AUTOSAR XML (schema 4-2-2)
package /STELLANTIS/EPT/ASWCs
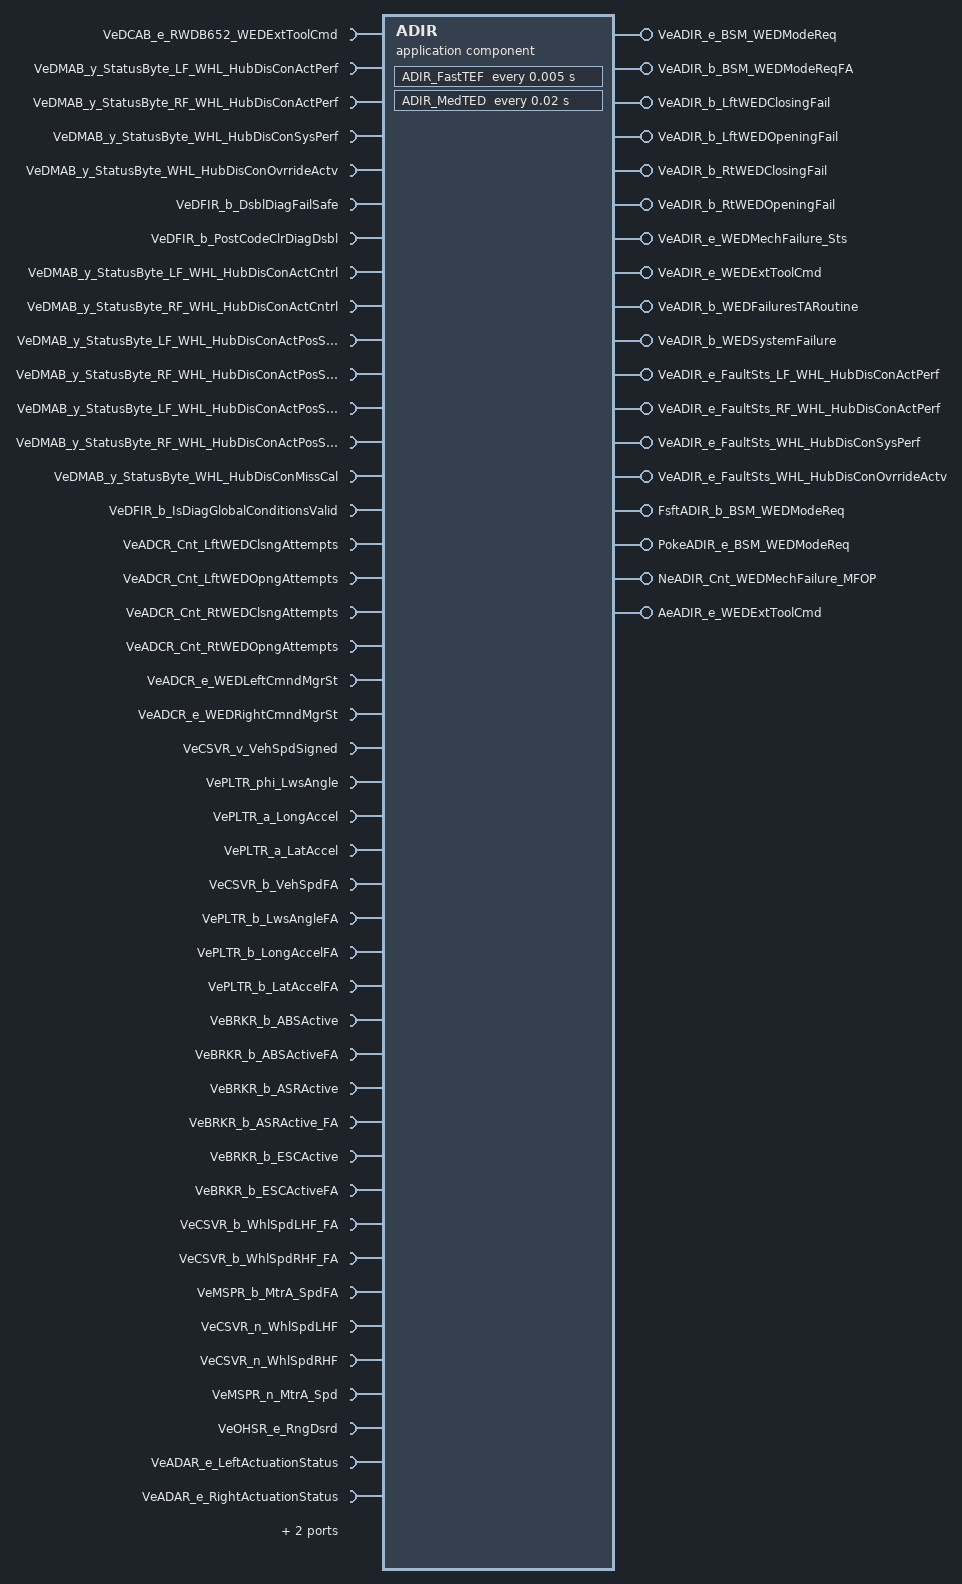
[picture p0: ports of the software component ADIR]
  application sw component type ADIR
    44 x require port:
      VeDCAB_e_RWDB652_WEDExtToolCmd: variation-point={short-label=vpVeDCAB_e_RWDB652_WEDExtToolCmd, sw-syscond=1}, nonqueued-receiver-com-spec{data-element=Value, init-value=CeADIR_e_ECUNormalControl}, required-interface=VeDCAB_e_RWDB652_WEDExtToolCmd
      VeDMAB_y_StatusByte_LF_WHL_HubDisConActPerf: variation-point={short-label=vpVeDMAB_y_StatusByte_LF_WHL_HubDisConActPerf, sw-syscond=1}, nonqueued-receiver-com-spec{data-element=Value, init-value=0}, required-interface=VeDMAB_y_StatusByte_LF_WHL_HubDisConActPerf
      VeDMAB_y_StatusByte_RF_WHL_HubDisConActPerf: variation-point={short-label=vpVeDMAB_y_StatusByte_RF_WHL_HubDisConActPerf, sw-syscond=1}, nonqueued-receiver-com-spec{data-element=Value, init-value=0}, required-interface=VeDMAB_y_StatusByte_RF_WHL_HubDisConActPerf
      VeDMAB_y_StatusByte_WHL_HubDisConSysPerf: variation-point={short-label=vpVeDMAB_y_StatusByte_WHL_HubDisConSysPerf, sw-syscond=1}, nonqueued-receiver-com-spec{data-element=Value, init-value=0}, required-interface=VeDMAB_y_StatusByte_WHL_HubDisConSysPerf
      VeDMAB_y_StatusByte_WHL_HubDisConOvrrideActv: variation-point={short-label=vpVeDMAB_y_StatusByte_WHL_HubDisConOvrrideActv, sw-syscond=1}, nonqueued-receiver-com-spec{data-element=Value, init-value=0}, required-interface=VeDMAB_y_StatusByte_WHL_HubDisConOvrrideActv
      VeDFIR_b_DsblDiagFailSafe: variation-point={short-label=vpVeDFIR_b_DsblDiagFailSafe, sw-syscond=1}, nonqueued-receiver-com-spec{data-element=Value, init-value=0}, required-interface=VeDFIR_b_DsblDiagFailSafe
      VeDFIR_b_PostCodeClrDiagDsbl: variation-point={short-label=vpVeDFIR_b_PostCodeClrDiagDsbl, sw-syscond=1}, nonqueued-receiver-com-spec{data-element=Value, init-value=0}, required-interface=VeDFIR_b_PostCodeClrDiagDsbl
      VeDMAB_y_StatusByte_LF_WHL_HubDisConActCntrl: variation-point={short-label=vpVeDMAB_y_StatusByte_LF_WHL_HubDisConActCntrl, sw-syscond=1}, nonqueued-receiver-com-spec{data-element=Value, init-value=0}, required-interface=VeDMAB_y_StatusByte_LF_WHL_HubDisConActCntrl
      VeDMAB_y_StatusByte_RF_WHL_HubDisConActCntrl: variation-point={short-label=vpVeDMAB_y_StatusByte_RF_WHL_HubDisConActCntrl, sw-syscond=1}, nonqueued-receiver-com-spec{data-element=Value, init-value=0}, required-interface=VeDMAB_y_StatusByte_RF_WHL_HubDisConActCntrl
      VeDMAB_y_StatusByte_LF_WHL_HubDisConActPosSnsr: variation-point={short-label=vpVeDMAB_y_StatusByte_LF_WHL_HubDisConActPosSnsr, sw-syscond=1}, nonqueued-receiver-com-spec{data-element=Value, init-value=0}, required-interface=VeDMAB_y_StatusByte_LF_WHL_HubDisConActPosSnsr
      VeDMAB_y_StatusByte_RF_WHL_HubDisConActPosSnsr: variation-point={short-label=vpVeDMAB_y_StatusByte_RF_WHL_HubDisConActPosSnsr, sw-syscond=1}, nonqueued-receiver-com-spec{data-element=Value, init-value=0}, required-interface=VeDMAB_y_StatusByte_RF_WHL_HubDisConActPosSnsr
      VeDMAB_y_StatusByte_LF_WHL_HubDisConActPosSnsrCktPerf: variation-point={short-label=vpVeDMAB_y_StatusByte_LF_WHL_HubDisConActPosSnsrCktPerf, sw-syscond=1}, nonqueued-receiver-com-spec{data-element=Value, init-value=0}, required-interface=VeDMAB_y_StatusByte_LF_WHL_HubDisConActPosSnsrCktPerf
      VeDMAB_y_StatusByte_RF_WHL_HubDisConActPosSnsrCktPerf: variation-point={short-label=vpVeDMAB_y_StatusByte_RF_WHL_HubDisConActPosSnsrCktPerf, sw-syscond=1}, nonqueued-receiver-com-spec{data-element=Value, init-value=0}, required-interface=VeDMAB_y_StatusByte_RF_WHL_HubDisConActPosSnsrCktPerf
      VeDMAB_y_StatusByte_WHL_HubDisConMissCal: variation-point={short-label=vpVeDMAB_y_StatusByte_WHL_HubDisConMissCal, sw-syscond=1}, nonqueued-receiver-com-spec{data-element=Value, init-value=0}, required-interface=VeDMAB_y_StatusByte_WHL_HubDisConMissCal
      VeDFIR_b_IsDiagGlobalConditionsValid: variation-point={short-label=vpVeDFIR_b_IsDiagGlobalConditionsValid, sw-syscond=1}, nonqueued-receiver-com-spec{data-element=Value, init-value=0}, required-interface=VeDFIR_b_IsDiagGlobalConditionsValid
      VeADCR_Cnt_LftWEDClsngAttempts: variation-point={short-label=vpVeADCR_Cnt_LftWEDClsngAttempts, sw-syscond=1}, nonqueued-receiver-com-spec{data-element=Value, init-value=0}, required-interface=VeADCR_Cnt_LftWEDClsngAttempts
      VeADCR_Cnt_LftWEDOpngAttempts: variation-point={short-label=vpVeADCR_Cnt_LftWEDOpngAttempts, sw-syscond=1}, nonqueued-receiver-com-spec{data-element=Value, init-value=0}, required-interface=VeADCR_Cnt_LftWEDOpngAttempts
      VeADCR_Cnt_RtWEDClsngAttempts: variation-point={short-label=vpVeADCR_Cnt_RtWEDClsngAttempts, sw-syscond=1}, nonqueued-receiver-com-spec{data-element=Value, init-value=0}, required-interface=VeADCR_Cnt_RtWEDClsngAttempts
      VeADCR_Cnt_RtWEDOpngAttempts: variation-point={short-label=vpVeADCR_Cnt_RtWEDOpngAttempts, sw-syscond=1}, nonqueued-receiver-com-spec{data-element=Value, init-value=0}, required-interface=VeADCR_Cnt_RtWEDOpngAttempts
      VeADCR_e_WEDLeftCmndMgrSt: variation-point={short-label=vpVeADCR_e_WEDLeftCmndMgrSt, sw-syscond=1}, nonqueued-receiver-com-spec{data-element=Value, init-value=CeADCR_e_WEDCmndInit}, required-interface=VeADCR_e_WEDLeftCmndMgrSt
      VeADCR_e_WEDRightCmndMgrSt: variation-point={short-label=vpVeADCR_e_WEDRightCmndMgrSt, sw-syscond=1}, nonqueued-receiver-com-spec{data-element=Value, init-value=CeADCR_e_WEDCmndInit}, required-interface=VeADCR_e_WEDRightCmndMgrSt
      VeCSVR_v_VehSpdSigned: variation-point={short-label=vpVeCSVR_v_VehSpdSigned, sw-syscond=1}, nonqueued-receiver-com-spec{data-element=Value, init-value=0}, required-interface=VeCSVR_v_VehSpdSigned
      VePLTR_phi_LwsAngle: variation-point={short-label=vpVePLTR_phi_LwsAngle, sw-syscond=1}, nonqueued-receiver-com-spec{data-element=Value, init-value=0}, required-interface=VePLTR_phi_LwsAngle
      VePLTR_a_LongAccel: variation-point={short-label=vpVePLTR_a_LongAccel, sw-syscond=1}, nonqueued-receiver-com-spec{data-element=Value, init-value=0}, required-interface=VePLTR_a_LongAccel
      VePLTR_a_LatAccel: variation-point={short-label=vpVePLTR_a_LatAccel, sw-syscond=1}, nonqueued-receiver-com-spec{data-element=Value, init-value=0}, required-interface=VePLTR_a_LatAccel
      VeCSVR_b_VehSpdFA: variation-point={short-label=vpVeCSVR_b_VehSpdFA, sw-syscond=1}, nonqueued-receiver-com-spec{data-element=Value, init-value=0}, required-interface=VeCSVR_b_VehSpdFA
      VePLTR_b_LwsAngleFA: variation-point={short-label=vpVePLTR_b_LwsAngleFA, sw-syscond=1}, nonqueued-receiver-com-spec{data-element=Value, init-value=0}, required-interface=VePLTR_b_LwsAngleFA
      VePLTR_b_LongAccelFA: variation-point={short-label=vpVePLTR_b_LongAccelFA, sw-syscond=1}, nonqueued-receiver-com-spec{data-element=Value, init-value=0}, required-interface=VePLTR_b_LongAccelFA
      VePLTR_b_LatAccelFA: variation-point={short-label=vpVePLTR_b_LatAccelFA, sw-syscond=1}, nonqueued-receiver-com-spec{data-element=Value, init-value=0}, required-interface=VePLTR_b_LatAccelFA
      VeBRKR_b_ABSActive: variation-point={short-label=vpVeBRKR_b_ABSActive, sw-syscond=1}, nonqueued-receiver-com-spec{data-element=Value, init-value=0}, required-interface=VeBRKR_b_ABSActive
      VeBRKR_b_ABSActiveFA: variation-point={short-label=vpVeBRKR_b_ABSActiveFA, sw-syscond=1}, nonqueued-receiver-com-spec{data-element=Value, init-value=0}, required-interface=VeBRKR_b_ABSActiveFA
      VeBRKR_b_ASRActive: variation-point={short-label=vpVeBRKR_b_ASRActive, sw-syscond=1}, nonqueued-receiver-com-spec{data-element=Value, init-value=0}, required-interface=VeBRKR_b_ASRActive
      VeBRKR_b_ASRActive_FA: variation-point={short-label=vpVeBRKR_b_ASRActive_FA, sw-syscond=1}, nonqueued-receiver-com-spec{data-element=Value, init-value=0}, required-interface=VeBRKR_b_ASRActive_FA
      VeBRKR_b_ESCActive: variation-point={short-label=vpVeBRKR_b_ESCActive, sw-syscond=1}, nonqueued-receiver-com-spec{data-element=Value, init-value=0}, required-interface=VeBRKR_b_ESCActive
      VeBRKR_b_ESCActiveFA: variation-point={short-label=vpVeBRKR_b_ESCActiveFA, sw-syscond=1}, nonqueued-receiver-com-spec{data-element=Value, init-value=0}, required-interface=VeBRKR_b_ESCActiveFA
      VeCSVR_b_WhlSpdLHF_FA: variation-point={short-label=vpVeCSVR_b_WhlSpdLHF_FA, sw-syscond=1}, nonqueued-receiver-com-spec{data-element=Value, init-value=0}, required-interface=VeCSVR_b_WhlSpdLHF_FA
      VeCSVR_b_WhlSpdRHF_FA: variation-point={short-label=vpVeCSVR_b_WhlSpdRHF_FA, sw-syscond=1}, nonqueued-receiver-com-spec{data-element=Value, init-value=0}, required-interface=VeCSVR_b_WhlSpdRHF_FA
      VeMSPR_b_MtrA_SpdFA: variation-point={short-label=vpVeMSPR_b_MtrA_SpdFA, sw-syscond=1}, nonqueued-receiver-com-spec{data-element=Value, init-value=0}, required-interface=VeMSPR_b_MtrA_SpdFA
      VeCSVR_n_WhlSpdLHF: variation-point={short-label=vpVeCSVR_n_WhlSpdLHF, sw-syscond=1}, nonqueued-receiver-com-spec{data-element=Value, init-value=0}, required-interface=VeCSVR_n_WhlSpdLHF
      VeCSVR_n_WhlSpdRHF: variation-point={short-label=vpVeCSVR_n_WhlSpdRHF, sw-syscond=1}, nonqueued-receiver-com-spec{data-element=Value, init-value=0}, required-interface=VeCSVR_n_WhlSpdRHF
      VeMSPR_n_MtrA_Spd: variation-point={short-label=vpVeMSPR_n_MtrA_Spd, sw-syscond=1}, nonqueued-receiver-com-spec{data-element=Value, init-value=0}, required-interface=VeMSPR_n_MtrA_Spd
      VeOHSR_e_RngDsrd: variation-point={short-label=vpVeOHSR_e_RngDsrd, sw-syscond=1}, nonqueued-receiver-com-spec{data-element=Value, init-value=CeOHSR_e_RngSel_N}, required-interface=VeOHSR_e_RngDsrd
      VeADAR_e_LeftActuationStatus: variation-point={short-label=vpVeADAR_e_LeftActuationStatus, sw-syscond=1}, nonqueued-receiver-com-spec{data-element=Value, init-value=CeADAR_e_SS_Indeterminate}, required-interface=VeADAR_e_LeftActuationStatus
      VeADAR_e_RightActuationStatus: variation-point={short-label=vpVeADAR_e_RightActuationStatus, sw-syscond=1}, nonqueued-receiver-com-spec{data-element=Value, init-value=CeADAR_e_SS_Indeterminate}, required-interface=VeADAR_e_RightActuationStatus
    16 x provide port:
      VeADIR_e_BSM_WEDModeReq: nonqueued-sender-com-spec{data-element=Value, init-value=CeADCR_e_ReqOpt}, provided-interface=VeADIR_e_BSM_WEDModeReq
      VeADIR_b_BSM_WEDModeReqFA: nonqueued-sender-com-spec{data-element=Value, init-value=0}, provided-interface=VeADIR_b_BSM_WEDModeReqFA
      VeADIR_b_LftWEDClosingFail: nonqueued-sender-com-spec{data-element=Value, init-value=0}, provided-interface=VeADIR_b_LftWEDClosingFail
      VeADIR_b_LftWEDOpeningFail: nonqueued-sender-com-spec{data-element=Value, init-value=0}, provided-interface=VeADIR_b_LftWEDOpeningFail
      VeADIR_b_RtWEDClosingFail: nonqueued-sender-com-spec{data-element=Value, init-value=0}, provided-interface=VeADIR_b_RtWEDClosingFail
      VeADIR_b_RtWEDOpeningFail: nonqueued-sender-com-spec{data-element=Value, init-value=0}, provided-interface=VeADIR_b_RtWEDOpeningFail
      VeADIR_e_WEDMechFailure_Sts: nonqueued-sender-com-spec{data-element=Value, init-value=CeADIR_e_BreakageNotTested}, provided-interface=VeADIR_e_WEDMechFailure_Sts
      VeADIR_e_WEDExtToolCmd: nonqueued-sender-com-spec{data-element=Value, init-value=CeADIR_e_ECUNormalControl}, provided-interface=VeADIR_e_WEDExtToolCmd
      VeADIR_b_WEDFailuresTARoutine: nonqueued-sender-com-spec{data-element=Value, init-value=0}, provided-interface=VeADIR_b_WEDFailuresTARoutine
      VeADIR_b_WEDSystemFailure: nonqueued-sender-com-spec{data-element=Value, init-value=0}, provided-interface=VeADIR_b_WEDSystemFailure
      VeADIR_e_FaultSts_LF_WHL_HubDisConActPerf: nonqueued-sender-com-spec{data-element=Value, init-value=CeDFIB_e_Init}, provided-interface=VeADIR_e_FaultSts_LF_WHL_HubDisConActPerf
      VeADIR_e_FaultSts_RF_WHL_HubDisConActPerf: nonqueued-sender-com-spec{data-element=Value, init-value=CeDFIB_e_Init}, provided-interface=VeADIR_e_FaultSts_RF_WHL_HubDisConActPerf
      VeADIR_e_FaultSts_WHL_HubDisConSysPerf: nonqueued-sender-com-spec{data-element=Value, init-value=CeDFIB_e_Init}, provided-interface=VeADIR_e_FaultSts_WHL_HubDisConSysPerf
      VeADIR_e_FaultSts_WHL_HubDisConOvrrideActv: nonqueued-sender-com-spec{data-element=Value, init-value=CeDFIB_e_Init}, provided-interface=VeADIR_e_FaultSts_WHL_HubDisConOvrrideActv
      FsftADIR_b_BSM_WEDModeReq: server-com-spec=FsftADIR_b_BSM_WEDModeReq, provided-interface=FsftADIR_b_BSM_WEDModeReq
      PokeADIR_e_BSM_WEDModeReq: server-com-spec{operation=PokeADIR_e_BSM_WEDModeReq, queue-length=1}, provided-interface=PokeADIR_e_BSM_WEDModeReq
    require port NeADIR_Cnt_WEDMechFailure_MFOP_Rx: nv-require-com-spec{init-value=0, variable=NeADIR_Cnt_WEDMechFailure_MFOP}, required-interface=NeADIR_Cnt_WEDMechFailure_MFOP
    require port AeADIR_e_WEDExtToolCmd_Rx: nv-require-com-spec{init-value=CeADIR_e_ECUNormalControl, variable=AeADIR_e_WEDExtToolCmd}, required-interface=AeADIR_e_WEDExtToolCmd
    provide port NeADIR_Cnt_WEDMechFailure_MFOP: nv-provide-com-spec{ram-block-init-value=0, variable=NeADIR_Cnt_WEDMechFailure_MFOP}, provided-interface=NeADIR_Cnt_WEDMechFailure_MFOP
    provide port AeADIR_e_WEDExtToolCmd: variation-point={short-label=vpAeADIR_e_WEDExtToolCmd, sw-syscond=1}, nv-provide-com-spec{ram-block-init-value=CeADIR_e_ECUNormalControl, variable=AeADIR_e_WEDExtToolCmd}, provided-interface=AeADIR_e_WEDExtToolCmd
    behavior IB_ADIR: data-type-mapping=msADTtoIDTMapping, handle-termination-and-restart=NO-SUPPORT, included-data-type-set=data-type=[TeADIR_e_WEDFailureDiagState, TeADIR_e_WEDRetryDiagState]
      timing event Event_FastTEF: start-on-event=ADIR_FastTEF, period=0.005
      timing event Event_MedTED: start-on-event=ADIR_MedTED, period=0.02
      operation invoked event Event_FsftADIR_b_BSM_WEDModeReq: start-on-event=FsftADIR_b_BSM_WEDModeReq, operation=FsftADIR_b_BSM_WEDModeReq.FsftADIR_b_BSM_WEDModeReq
      operation invoked event Event_PokeADIR_e_BSM_WEDModeReq: start-on-event=PokeADIR_e_BSM_WEDModeReq, operation=PokeADIR_e_BSM_WEDModeReq.PokeADIR_e_BSM_WEDModeReq
      init event Event_ADIR_ac_Init: start-on-event=ADIR_ac_Init
      init event Event_PwrOn: start-on-event=ADIR_PwrOn
      data received event Event_DidWrite_RWDB652_WEDExtToolCmd: start-on-event=DidWrite_RWDB652_WEDExtToolCmd, data=VeDCAB_e_RWDB652_WEDExtToolCmd.Value
      init event Event_PwrOff: start-on-event=ADIR_PwrOff
      explicit-inter-runnable-variables:
        data BSM_WEDModeReq_Init_IRV_IRV: category=VALUE, sw-calibration-access=READ-ONLY, type=TeADCR_e_AWDReq, init-value=CeADCR_e_ReqOpt, variation-point={short-label=vpBSM_WEDModeReq_Init_IRV_IRV, sw-syscond=1}
        data BSM_WEDModeReqFA_Init_IRV_IRV: category=VALUE, sw-calibration-access=READ-ONLY, type=Boolean, init-value=0, variation-point={short-label=vpBSM_WEDModeReqFA_Init_IRV_IRV, sw-syscond=1}
        data WEDExtToolCmd_Init_IRV_IRV: category=VALUE, sw-calibration-access=READ-ONLY, type=TeADIR_e_WEDExtToolCmd, init-value=CeADIR_e_ECUNormalControl, variation-point={short-label=vpWEDExtToolCmd_Init_IRV_IRV, sw-syscond=1}
      8 x runnable:
        ADIR_ac_Init
          data-send-points:
            7 x access:
              OUT_VeADIR_e_BSM_WEDModeReq_Value: accessed-variable=VeADIR_e_BSM_WEDModeReq.Value
              OUT_VeADIR_e_WEDMechFailure_Sts_Value: accessed-variable=VeADIR_e_WEDMechFailure_Sts.Value
              OUT_VeADIR_e_WEDExtToolCmd_Value: accessed-variable=VeADIR_e_WEDExtToolCmd.Value
              OUT_VeADIR_e_FaultSts_LF_WHL_HubDisConActPerf_Value: accessed-variable=VeADIR_e_FaultSts_LF_WHL_HubDisConActPerf.Value
              OUT_VeADIR_e_FaultSts_RF_WHL_HubDisConActPerf_Value: accessed-variable=VeADIR_e_FaultSts_RF_WHL_HubDisConActPerf.Value
              OUT_VeADIR_e_FaultSts_WHL_HubDisConSysPerf_Value: accessed-variable=VeADIR_e_FaultSts_WHL_HubDisConSysPerf.Value
              OUT_VeADIR_e_FaultSts_WHL_HubDisConOvrrideActv_Value: accessed-variable=VeADIR_e_FaultSts_WHL_HubDisConOvrrideActv.Value
        ADIR_PwrOn
          data-receive-point-by-arguments:
            access IN_AeADIR_e_WEDExtToolCmd_Rx_AeADIR_e_WEDExtToolCmd: accessed-variable=AeADIR_e_WEDExtToolCmd_Rx.AeADIR_e_WEDExtToolCmd
            access IN_NeADIR_Cnt_WEDMechFailure_MFOP_Rx_NeADIR_Cnt_WEDMechFailure_MFOP: accessed-variable=NeADIR_Cnt_WEDMechFailure_MFOP_Rx.NeADIR_Cnt_WEDMechFailure_MFOP
          data-send-points:
            14 x access:
              OUT_VeADIR_b_LftWEDClosingFail_Value: accessed-variable=VeADIR_b_LftWEDClosingFail.Value
              OUT_VeADIR_b_LftWEDOpeningFail_Value: accessed-variable=VeADIR_b_LftWEDOpeningFail.Value
              OUT_VeADIR_b_RtWEDClosingFail_Value: accessed-variable=VeADIR_b_RtWEDClosingFail.Value
              OUT_VeADIR_b_RtWEDOpeningFail_Value: accessed-variable=VeADIR_b_RtWEDOpeningFail.Value
              OUT_VeADIR_e_WEDMechFailure_Sts_Value: accessed-variable=VeADIR_e_WEDMechFailure_Sts.Value
              OUT_VeADIR_e_BSM_WEDModeReq_Value: accessed-variable=VeADIR_e_BSM_WEDModeReq.Value
              OUT_VeADIR_b_BSM_WEDModeReqFA_Value: accessed-variable=VeADIR_b_BSM_WEDModeReqFA.Value
              OUT_VeADIR_e_WEDExtToolCmd_Value: accessed-variable=VeADIR_e_WEDExtToolCmd.Value
              OUT_VeADIR_b_WEDFailuresTARoutine_Value: accessed-variable=VeADIR_b_WEDFailuresTARoutine.Value
              OUT_VeADIR_b_WEDSystemFailure_Value: accessed-variable=VeADIR_b_WEDSystemFailure.Value
              OUT_VeADIR_e_FaultSts_LF_WHL_HubDisConActPerf_Value: accessed-variable=VeADIR_e_FaultSts_LF_WHL_HubDisConActPerf.Value
              OUT_VeADIR_e_FaultSts_RF_WHL_HubDisConActPerf_Value: accessed-variable=VeADIR_e_FaultSts_RF_WHL_HubDisConActPerf.Value
              OUT_VeADIR_e_FaultSts_WHL_HubDisConSysPerf_Value: accessed-variable=VeADIR_e_FaultSts_WHL_HubDisConSysPerf.Value
              OUT_VeADIR_e_FaultSts_WHL_HubDisConOvrrideActv_Value: accessed-variable=VeADIR_e_FaultSts_WHL_HubDisConOvrrideActv.Value
          written-local-variables:
            access WV_BSM_WEDModeReqFA_Init_IRV_IRV: accessed-variable=BSM_WEDModeReqFA_Init_IRV_IRV, variation-point={short-label=vpWV_BSM_WEDModeReqFA_Init_IRV_IRV, sw-syscond=1}
            access WV_BSM_WEDModeReq_Init_IRV_IRV: accessed-variable=BSM_WEDModeReq_Init_IRV_IRV, variation-point={short-label=vpWV_BSM_WEDModeReq_Init_IRV_IRV, sw-syscond=1}
            access WV_WEDExtToolCmd_Init_IRV_IRV: accessed-variable=WEDExtToolCmd_Init_IRV_IRV, variation-point={short-label=vpWV_WEDExtToolCmd_Init_IRV_IRV, sw-syscond=1}
        DidWrite_RWDB652_WEDExtToolCmd: variation-point={short-label=vpDidWrite_RWDB652_WEDExtToolCmd, sw-syscond=1}
          data-receive-point-by-arguments:
            access IN_VeDCAB_e_RWDB652_WEDExtToolCmd_Value: accessed-variable=VeDCAB_e_RWDB652_WEDExtToolCmd.Value, variation-point={short-label=vpIN_VeDCAB_e_RWDB652_WEDExtToolCmd_Value, sw-syscond=1}
          written-local-variables:
            access WV_WEDExtToolCmd_Init_IRV_IRV: accessed-variable=WEDExtToolCmd_Init_IRV_IRV, variation-point={short-label=vpWV_WEDExtToolCmd_Init_IRV_IRV, sw-syscond=1}
        ADIR_FastTEF: variation-point={short-label=vpADIR_FastTEF, sw-syscond=1}
          data-send-points:
            access OUT_VeADIR_e_BSM_WEDModeReq_Value: accessed-variable=VeADIR_e_BSM_WEDModeReq.Value
            access OUT_VeADIR_b_BSM_WEDModeReqFA_Value: accessed-variable=VeADIR_b_BSM_WEDModeReqFA.Value
          read-local-variables:
            access RV_BSM_WEDModeReqFA_Init_IRV_IRV: accessed-variable=BSM_WEDModeReqFA_Init_IRV_IRV, variation-point={short-label=vpRV_BSM_WEDModeReqFA_Init_IRV_IRV, sw-syscond=1}
            access RV_BSM_WEDModeReq_Init_IRV_IRV: accessed-variable=BSM_WEDModeReq_Init_IRV_IRV, variation-point={short-label=vpRV_BSM_WEDModeReq_Init_IRV_IRV, sw-syscond=1}
        ADIR_MedTED: variation-point={short-label=vpADIR_MedTED, sw-syscond=1}
          data-receive-point-by-arguments:
            43 x access:
              IN_VeADAR_e_LeftActuationStatus_Value: accessed-variable=VeADAR_e_LeftActuationStatus.Value, variation-point={short-label=vpIN_VeADAR_e_LeftActuationStatus_Value, sw-syscond=1}
              IN_VeADAR_e_RightActuationStatus_Value: accessed-variable=VeADAR_e_RightActuationStatus.Value, variation-point={short-label=vpIN_VeADAR_e_RightActuationStatus_Value, sw-syscond=1}
              IN_VeADCR_Cnt_LftWEDClsngAttempts_Value: accessed-variable=VeADCR_Cnt_LftWEDClsngAttempts.Value, variation-point={short-label=vpIN_VeADCR_Cnt_LftWEDClsngAttempts_Value, sw-syscond=1}
              IN_VeADCR_Cnt_LftWEDOpngAttempts_Value: accessed-variable=VeADCR_Cnt_LftWEDOpngAttempts.Value, variation-point={short-label=vpIN_VeADCR_Cnt_LftWEDOpngAttempts_Value, sw-syscond=1}
              IN_VeADCR_Cnt_RtWEDClsngAttempts_Value: accessed-variable=VeADCR_Cnt_RtWEDClsngAttempts.Value, variation-point={short-label=vpIN_VeADCR_Cnt_RtWEDClsngAttempts_Value, sw-syscond=1}
              IN_VeADCR_Cnt_RtWEDOpngAttempts_Value: accessed-variable=VeADCR_Cnt_RtWEDOpngAttempts.Value, variation-point={short-label=vpIN_VeADCR_Cnt_RtWEDOpngAttempts_Value, sw-syscond=1}
              IN_VeADCR_e_WEDLeftCmndMgrSt_Value: accessed-variable=VeADCR_e_WEDLeftCmndMgrSt.Value, variation-point={short-label=vpIN_VeADCR_e_WEDLeftCmndMgrSt_Value, sw-syscond=1}
              IN_VeADCR_e_WEDRightCmndMgrSt_Value: accessed-variable=VeADCR_e_WEDRightCmndMgrSt.Value, variation-point={short-label=vpIN_VeADCR_e_WEDRightCmndMgrSt_Value, sw-syscond=1}
              IN_VeBRKR_b_ABSActive_Value: accessed-variable=VeBRKR_b_ABSActive.Value, variation-point={short-label=vpIN_VeBRKR_b_ABSActive_Value, sw-syscond=1}
              IN_VeBRKR_b_ABSActiveFA_Value: accessed-variable=VeBRKR_b_ABSActiveFA.Value, variation-point={short-label=vpIN_VeBRKR_b_ABSActiveFA_Value, sw-syscond=1}
              IN_VeBRKR_b_ASRActive_Value: accessed-variable=VeBRKR_b_ASRActive.Value, variation-point={short-label=vpIN_VeBRKR_b_ASRActive_Value, sw-syscond=1}
              IN_VeBRKR_b_ASRActive_FA_Value: accessed-variable=VeBRKR_b_ASRActive_FA.Value, variation-point={short-label=vpIN_VeBRKR_b_ASRActive_FA_Value, sw-syscond=1}
              IN_VeBRKR_b_ESCActive_Value: accessed-variable=VeBRKR_b_ESCActive.Value, variation-point={short-label=vpIN_VeBRKR_b_ESCActive_Value, sw-syscond=1}
              IN_VeBRKR_b_ESCActiveFA_Value: accessed-variable=VeBRKR_b_ESCActiveFA.Value, variation-point={short-label=vpIN_VeBRKR_b_ESCActiveFA_Value, sw-syscond=1}
              IN_VeCSVR_b_VehSpdFA_Value: accessed-variable=VeCSVR_b_VehSpdFA.Value, variation-point={short-label=vpIN_VeCSVR_b_VehSpdFA_Value, sw-syscond=1}
              IN_VeCSVR_b_WhlSpdLHF_FA_Value: accessed-variable=VeCSVR_b_WhlSpdLHF_FA.Value, variation-point={short-label=vpIN_VeCSVR_b_WhlSpdLHF_FA_Value, sw-syscond=1}
              IN_VeCSVR_b_WhlSpdRHF_FA_Value: accessed-variable=VeCSVR_b_WhlSpdRHF_FA.Value, variation-point={short-label=vpIN_VeCSVR_b_WhlSpdRHF_FA_Value, sw-syscond=1}
              IN_VeCSVR_n_WhlSpdLHF_Value: accessed-variable=VeCSVR_n_WhlSpdLHF.Value, variation-point={short-label=vpIN_VeCSVR_n_WhlSpdLHF_Value, sw-syscond=1}
              IN_VeCSVR_n_WhlSpdRHF_Value: accessed-variable=VeCSVR_n_WhlSpdRHF.Value, variation-point={short-label=vpIN_VeCSVR_n_WhlSpdRHF_Value, sw-syscond=1}
              IN_VeCSVR_v_VehSpdSigned_Value: accessed-variable=VeCSVR_v_VehSpdSigned.Value, variation-point={short-label=vpIN_VeCSVR_v_VehSpdSigned_Value, sw-syscond=1}
              IN_VeDFIR_b_DsblDiagFailSafe_Value: accessed-variable=VeDFIR_b_DsblDiagFailSafe.Value, variation-point={short-label=vpIN_VeDFIR_b_DsblDiagFailSafe_Value, sw-syscond=1}
              IN_VeDFIR_b_IsDiagGlobalConditionsValid_Value: accessed-variable=VeDFIR_b_IsDiagGlobalConditionsValid.Value, variation-point={short-label=vpIN_VeDFIR_b_IsDiagGlobalConditionsValid_Value, sw-syscond=1}
              IN_VeDFIR_b_PostCodeClrDiagDsbl_Value: accessed-variable=VeDFIR_b_PostCodeClrDiagDsbl.Value, variation-point={short-label=vpIN_VeDFIR_b_PostCodeClrDiagDsbl_Value, sw-syscond=1}
              IN_VeDMAB_y_StatusByte_LF_WHL_HubDisConActCntrl_Value: accessed-variable=VeDMAB_y_StatusByte_LF_WHL_HubDisConActCntrl.Value, variation-point={short-label=vpIN_VeDMAB_y_StatusByte_LF_WHL_HubDisConActCntrl_Value, sw-syscond=1}
              IN_VeDMAB_y_StatusByte_LF_WHL_HubDisConActPerf_Value: accessed-variable=VeDMAB_y_StatusByte_LF_WHL_HubDisConActPerf.Value, variation-point={short-label=vpIN_VeDMAB_y_StatusByte_LF_WHL_HubDisConActPerf_Value, sw-syscond=1}
              IN_VeDMAB_y_StatusByte_LF_WHL_HubDisConActPosSnsr_Value: accessed-variable=VeDMAB_y_StatusByte_LF_WHL_HubDisConActPosSnsr.Value, variation-point={short-label=vpIN_VeDMAB_y_StatusByte_LF_WHL_HubDisConActPosSnsr_Value, sw-syscond=1}
              IN_VeDMAB_y_StatusByte_LF_WHL_HubDisConActPosSnsrCktPerf_Value: accessed-variable=VeDMAB_y_StatusByte_LF_WHL_HubDisConActPosSnsrCktPerf.Value, variation-point={short-label=vpIN_VeDMAB_y_StatusByte_LF_WHL_HubDisConActPosSnsrCktPerf_Value, sw-syscond=1}
              IN_VeDMAB_y_StatusByte_RF_WHL_HubDisConActCntrl_Value: accessed-variable=VeDMAB_y_StatusByte_RF_WHL_HubDisConActCntrl.Value, variation-point={short-label=vpIN_VeDMAB_y_StatusByte_RF_WHL_HubDisConActCntrl_Value, sw-syscond=1}
              IN_VeDMAB_y_StatusByte_RF_WHL_HubDisConActPerf_Value: accessed-variable=VeDMAB_y_StatusByte_RF_WHL_HubDisConActPerf.Value, variation-point={short-label=vpIN_VeDMAB_y_StatusByte_RF_WHL_HubDisConActPerf_Value, sw-syscond=1}
              IN_VeDMAB_y_StatusByte_RF_WHL_HubDisConActPosSnsr_Value: accessed-variable=VeDMAB_y_StatusByte_RF_WHL_HubDisConActPosSnsr.Value, variation-point={short-label=vpIN_VeDMAB_y_StatusByte_RF_WHL_HubDisConActPosSnsr_Value, sw-syscond=1}
              IN_VeDMAB_y_StatusByte_RF_WHL_HubDisConActPosSnsrCktPerf_Value: accessed-variable=VeDMAB_y_StatusByte_RF_WHL_HubDisConActPosSnsrCktPerf.Value, variation-point={short-label=vpIN_VeDMAB_y_StatusByte_RF_WHL_HubDisConActPosSnsrCktPerf_Value, sw-syscond=1}
              IN_VeDMAB_y_StatusByte_WHL_HubDisConMissCal_Value: accessed-variable=VeDMAB_y_StatusByte_WHL_HubDisConMissCal.Value, variation-point={short-label=vpIN_VeDMAB_y_StatusByte_WHL_HubDisConMissCal_Value, sw-syscond=1}
              IN_VeDMAB_y_StatusByte_WHL_HubDisConOvrrideActv_Value: accessed-variable=VeDMAB_y_StatusByte_WHL_HubDisConOvrrideActv.Value, variation-point={short-label=vpIN_VeDMAB_y_StatusByte_WHL_HubDisConOvrrideActv_Value, sw-syscond=1}
              IN_VeDMAB_y_StatusByte_WHL_HubDisConSysPerf_Value: accessed-variable=VeDMAB_y_StatusByte_WHL_HubDisConSysPerf.Value, variation-point={short-label=vpIN_VeDMAB_y_StatusByte_WHL_HubDisConSysPerf_Value, sw-syscond=1}
              IN_VeMSPR_b_MtrA_SpdFA_Value: accessed-variable=VeMSPR_b_MtrA_SpdFA.Value, variation-point={short-label=vpIN_VeMSPR_b_MtrA_SpdFA_Value, sw-syscond=1}
              IN_VeMSPR_n_MtrA_Spd_Value: accessed-variable=VeMSPR_n_MtrA_Spd.Value, variation-point={short-label=vpIN_VeMSPR_n_MtrA_Spd_Value, sw-syscond=1}
              IN_VeOHSR_e_RngDsrd_Value: accessed-variable=VeOHSR_e_RngDsrd.Value, variation-point={short-label=vpIN_VeOHSR_e_RngDsrd_Value, sw-syscond=1}
              IN_VePLTR_a_LatAccel_Value: accessed-variable=VePLTR_a_LatAccel.Value, variation-point={short-label=vpIN_VePLTR_a_LatAccel_Value, sw-syscond=1}
              IN_VePLTR_a_LongAccel_Value: accessed-variable=VePLTR_a_LongAccel.Value, variation-point={short-label=vpIN_VePLTR_a_LongAccel_Value, sw-syscond=1}
              IN_VePLTR_b_LatAccelFA_Value: accessed-variable=VePLTR_b_LatAccelFA.Value, variation-point={short-label=vpIN_VePLTR_b_LatAccelFA_Value, sw-syscond=1}
              IN_VePLTR_b_LongAccelFA_Value: accessed-variable=VePLTR_b_LongAccelFA.Value, variation-point={short-label=vpIN_VePLTR_b_LongAccelFA_Value, sw-syscond=1}
              IN_VePLTR_b_LwsAngleFA_Value: accessed-variable=VePLTR_b_LwsAngleFA.Value, variation-point={short-label=vpIN_VePLTR_b_LwsAngleFA_Value, sw-syscond=1}
              IN_VePLTR_phi_LwsAngle_Value: accessed-variable=VePLTR_phi_LwsAngle.Value, variation-point={short-label=vpIN_VePLTR_phi_LwsAngle_Value, sw-syscond=1}
          data-send-points:
            13 x access:
              OUT_VeADIR_e_FaultSts_LF_WHL_HubDisConActPerf_Value: accessed-variable=VeADIR_e_FaultSts_LF_WHL_HubDisConActPerf.Value
              OUT_VeADIR_e_FaultSts_RF_WHL_HubDisConActPerf_Value: accessed-variable=VeADIR_e_FaultSts_RF_WHL_HubDisConActPerf.Value
              OUT_VeADIR_e_FaultSts_WHL_HubDisConSysPerf_Value: accessed-variable=VeADIR_e_FaultSts_WHL_HubDisConSysPerf.Value
              OUT_AeADIR_e_WEDExtToolCmd_AeADIR_e_WEDExtToolCmd: accessed-variable=AeADIR_e_WEDExtToolCmd.AeADIR_e_WEDExtToolCmd, variation-point={short-label=vpOUT_AeADIR_e_WEDExtToolCmd_AeADIR_e_WEDExtToolCmd, sw-syscond=1}
              OUT_VeADIR_e_FaultSts_WHL_HubDisConOvrrideActv_Value: accessed-variable=VeADIR_e_FaultSts_WHL_HubDisConOvrrideActv.Value
              OUT_VeADIR_b_LftWEDClosingFail_Value: accessed-variable=VeADIR_b_LftWEDClosingFail.Value
              OUT_VeADIR_b_LftWEDOpeningFail_Value: accessed-variable=VeADIR_b_LftWEDOpeningFail.Value
              OUT_VeADIR_b_RtWEDClosingFail_Value: accessed-variable=VeADIR_b_RtWEDClosingFail.Value
              OUT_VeADIR_b_RtWEDOpeningFail_Value: accessed-variable=VeADIR_b_RtWEDOpeningFail.Value
              OUT_VeADIR_e_WEDMechFailure_Sts_Value: accessed-variable=VeADIR_e_WEDMechFailure_Sts.Value
              OUT_VeADIR_e_WEDExtToolCmd_Value: accessed-variable=VeADIR_e_WEDExtToolCmd.Value
              OUT_VeADIR_b_WEDFailuresTARoutine_Value: accessed-variable=VeADIR_b_WEDFailuresTARoutine.Value
              OUT_VeADIR_b_WEDSystemFailure_Value: accessed-variable=VeADIR_b_WEDSystemFailure.Value
          read-local-variables:
            access RV_WEDExtToolCmd_Init_IRV_IRV: accessed-variable=WEDExtToolCmd_Init_IRV_IRV, variation-point={short-label=vpRV_WEDExtToolCmd_Init_IRV_IRV, sw-syscond=1}
        ADIR_PwrOff
          data-send-points:
            access OUT_NeADIR_Cnt_WEDMechFailure_MFOP_NeADIR_Cnt_WEDMechFailure_MFOP: accessed-variable=NeADIR_Cnt_WEDMechFailure_MFOP.NeADIR_Cnt_WEDMechFailure_MFOP
        FsftADIR_b_BSM_WEDModeReq
          written-local-variables:
            access WV_BSM_WEDModeReqFA_Init_IRV_IRV: accessed-variable=BSM_WEDModeReqFA_Init_IRV_IRV, variation-point={short-label=vpWV_BSM_WEDModeReqFA_Init_IRV_IRV, sw-syscond=1}
            access WV_BSM_WEDModeReq_Init_IRV_IRV: accessed-variable=BSM_WEDModeReq_Init_IRV_IRV, variation-point={short-label=vpWV_BSM_WEDModeReq_Init_IRV_IRV, sw-syscond=1}
        PokeADIR_e_BSM_WEDModeReq
          written-local-variables:
            access WV_BSM_WEDModeReqFA_Init_IRV_IRV: accessed-variable=BSM_WEDModeReqFA_Init_IRV_IRV, variation-point={short-label=vpWV_BSM_WEDModeReqFA_Init_IRV_IRV, sw-syscond=1}
            access WV_BSM_WEDModeReq_Init_IRV_IRV: accessed-variable=BSM_WEDModeReq_Init_IRV_IRV, variation-point={short-label=vpWV_BSM_WEDModeReq_Init_IRV_IRV, sw-syscond=1}
      variation point proxy Variant_ADIR_1: category=CONDITION, condition-access=1
